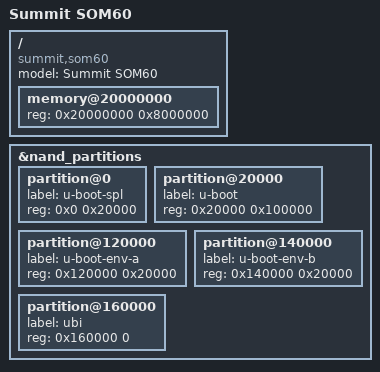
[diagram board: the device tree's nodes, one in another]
// SPDX-License-Identifier: GPL-2.0
/*
 * at91-som60.dtsi - Device Tree file for the SOM60 module
 *
 *  Copyright (C) 2018 Ezurio,
 *		  2018 Ben Whitten <ben.whitten@ezurio.com>
 *		  2018 Boris Krasnovskiy <boris.krasnovskiy@ezurio.com>
 *
 */
#include "at91-som60_common.dtsi"

/ {
	model = "Summit SOM60";
	compatible = "summit,som60", "atmel,sama5d36", "atmel,sama5d3", "atmel,sama5";

	memory@20000000 {
		reg = <0x20000000 0x8000000>;
	};
};

&nand_partitions {
	partition@0 {
		label = "u-boot-spl";
		reg = <0x0 0x20000>;
	};

	partition@20000 {
		label = "u-boot";
		reg = <0x20000 0x100000>;
	};

	partition@120000 {
		label = "u-boot-env-a";
		reg = <0x120000 0x20000>;
	};

	partition@140000 {
		label = "u-boot-env-b";
		reg = <0x140000 0x20000>;
	};

	/* Leave last 4 blocks for bbt if nand-on-flash-bbt is defined */
	partition@160000 {
		label = "ubi";
		reg = <0x160000 0>;
	};
};
